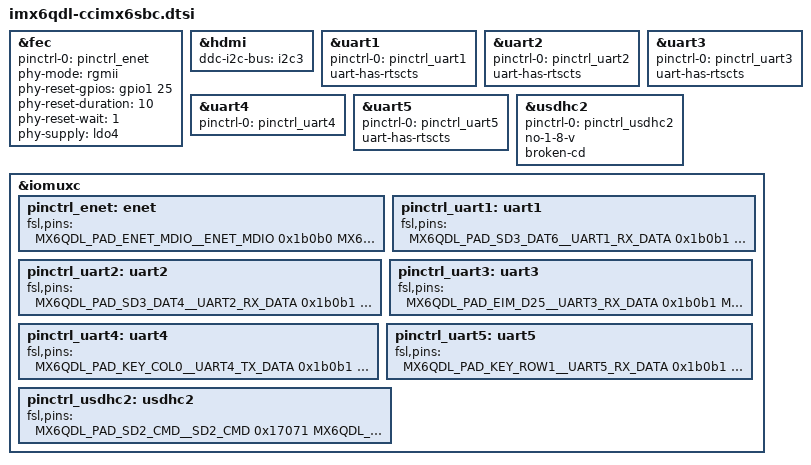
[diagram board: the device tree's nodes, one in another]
// SPDX-License-Identifier: GPL-2.0 OR X11
/*
 * Copyright 2019 Digi International, Inc.
 */

&fec {
	pinctrl-names = "default";
	pinctrl-0 = <&pinctrl_enet>;
	phy-mode = "rgmii";
	phy-reset-gpios = <&gpio1 25 GPIO_ACTIVE_HIGH>;
	phy-reset-duration = <10>;
	phy-reset-wait = <1>;
	phy-supply = <&ldo4>;
};

&hdmi {
	ddc-i2c-bus = <&i2c3>;
	status = "okay";
};

&uart1 {
	pinctrl-names = "default";
	pinctrl-0 = <&pinctrl_uart1>;
	uart-has-rtscts;
};

&uart2 {
	pinctrl-names = "default";
	pinctrl-0 = <&pinctrl_uart2>;
	uart-has-rtscts;
};

&uart3 {
	pinctrl-names = "default";
	pinctrl-0 = <&pinctrl_uart3>;
	uart-has-rtscts;
};

&uart4 {
	pinctrl-names = "default";
	pinctrl-0 = <&pinctrl_uart4>;
};

&uart5 {
	pinctrl-names = "default";
	pinctrl-0 = <&pinctrl_uart5>;
	uart-has-rtscts;
};


&usdhc2 {
	pinctrl-names = "default";
	pinctrl-0 = <&pinctrl_usdhc2>;
	no-1-8-v;
	broken-cd;
	status = "okay";
};

&iomuxc {
	pinctrl_enet: enet {
		fsl,pins = <
			MX6QDL_PAD_ENET_MDIO__ENET_MDIO		0x1b0b0
			MX6QDL_PAD_ENET_MDC__ENET_MDC		0x1b0b0
			MX6QDL_PAD_RGMII_TXC__RGMII_TXC		0x1b0b0
			MX6QDL_PAD_RGMII_TD0__RGMII_TD0		0x1b0b0
			MX6QDL_PAD_RGMII_TD1__RGMII_TD1		0x1b0b0
			MX6QDL_PAD_RGMII_TD2__RGMII_TD2		0x1b0b0
			MX6QDL_PAD_RGMII_TD3__RGMII_TD3		0x1b0b0
			MX6QDL_PAD_RGMII_TX_CTL__RGMII_TX_CTL	0x1b0b0
			MX6QDL_PAD_ENET_REF_CLK__ENET_TX_CLK	0x1b0b0
			MX6QDL_PAD_RGMII_RXC__RGMII_RXC		0x1b0b0
			MX6QDL_PAD_RGMII_RD0__RGMII_RD0		0x1b0b0
			MX6QDL_PAD_RGMII_RD1__RGMII_RD1		0x1b0b0
			MX6QDL_PAD_RGMII_RD2__RGMII_RD2		0x1b0b0
			MX6QDL_PAD_RGMII_RD3__RGMII_RD3		0x1b0b0
			MX6QDL_PAD_RGMII_RX_CTL__RGMII_RX_CTL	0x1b0b0
			MX6QDL_PAD_ENET_REF_CLK__ENET_TX_CLK	0x1b0b0
			MX6QDL_PAD_ENET_TX_EN__GPIO1_IO28	0x1b0b0
			MX6QDL_PAD_ENET_CRS_DV__GPIO1_IO25	0x1b0b0
		>;
	};

	pinctrl_uart1: uart1 {
		fsl,pins = <
			MX6QDL_PAD_SD3_DAT6__UART1_RX_DATA	0x1b0b1
			MX6QDL_PAD_SD3_DAT7__UART1_TX_DATA	0x1b0b1
			MX6QDL_PAD_EIM_D19__UART1_CTS_B		0x1b0b1
			MX6QDL_PAD_EIM_D20__UART1_RTS_B		0x1b0b1
		>;
	};

	pinctrl_uart2: uart2 {
		fsl,pins = <
			MX6QDL_PAD_SD3_DAT4__UART2_RX_DATA	0x1b0b1
			MX6QDL_PAD_SD3_DAT5__UART2_TX_DATA	0x1b0b1
			MX6QDL_PAD_SD3_CMD__UART2_CTS_B		0x1b0b1
			MX6QDL_PAD_SD3_CLK__UART2_RTS_B		0x1b0b1
		>;
	};

	pinctrl_uart3: uart3 {
		fsl,pins = <
			MX6QDL_PAD_EIM_D25__UART3_RX_DATA	0x1b0b1
			MX6QDL_PAD_EIM_D24__UART3_TX_DATA	0x1b0b1
			MX6QDL_PAD_EIM_D30__UART3_CTS_B		0x1b0b1
			MX6QDL_PAD_EIM_D31__UART3_RTS_B		0x1b0b1
		>;
	};

	pinctrl_uart4: uart4 {
		fsl,pins = <
			MX6QDL_PAD_KEY_COL0__UART4_TX_DATA	0x1b0b1
			MX6QDL_PAD_KEY_ROW0__UART4_RX_DATA	0x1b0b1
		>;
	};

	pinctrl_uart5: uart5 {
		fsl,pins = <
			MX6QDL_PAD_KEY_ROW1__UART5_RX_DATA	0x1b0b1
			MX6QDL_PAD_KEY_COL1__UART5_TX_DATA	0x1b0b1
			MX6QDL_PAD_KEY_COL4__UART5_RTS_B	0x1b0b1
			MX6QDL_PAD_KEY_ROW4__UART5_CTS_B	0x1b0b1
		>;
	};

	pinctrl_usdhc2: usdhc2 {
		fsl,pins = <
			MX6QDL_PAD_SD2_CMD__SD2_CMD		0x17071
			MX6QDL_PAD_SD2_CLK__SD2_CLK		0x10071
			MX6QDL_PAD_SD2_DAT0__SD2_DATA0		0x17071
			MX6QDL_PAD_SD2_DAT1__SD2_DATA1		0x17071
			MX6QDL_PAD_SD2_DAT2__SD2_DATA2		0x17071
			MX6QDL_PAD_SD2_DAT3__SD2_DATA3		0x17071
		>;
	};
};
